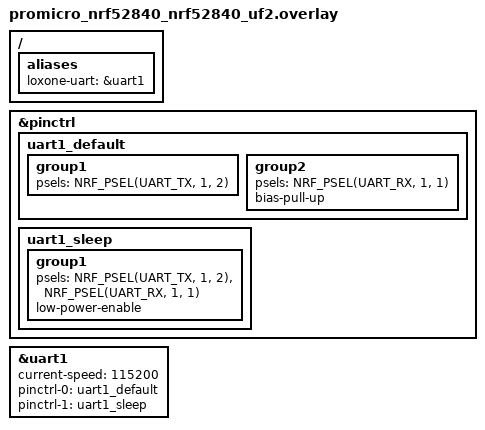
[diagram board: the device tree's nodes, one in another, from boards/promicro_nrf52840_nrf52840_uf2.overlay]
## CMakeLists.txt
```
# SPDX-License-Identifier: Apache-2.0

cmake_minimum_required(VERSION 3.20.0)
find_package(Zephyr REQUIRED HINTS $ENV{ZEPHYR_BASE})
project(Nuki)

target_sources(app PRIVATE
  src/main.c
  src/nuki_crypto.c
  src/nuki_protocol.c
  src/nuki_storage.c
  src/nuki_transport.c
  src/nuki_pairing.c
  src/nuki_command.c
  src/nuki_app.c
  src/nuki_shell.c
  src/nuki_uart_proto.c
)

zephyr_library_include_directories(${ZEPHYR_BASE}/samples/bluetooth)
```

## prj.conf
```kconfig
CONFIG_BT=y
CONFIG_BT_CENTRAL=y
CONFIG_BT_GATT_CLIENT=y
CONFIG_BT_GATT_DM=y
CONFIG_BT_SMP=n
CONFIG_BT_MAX_CONN=1
CONFIG_BT_DEVICE_NAME="Nuki Central"

# Nuki uses its own app-layer crypto (Curve25519 + HSalsa20/Salsa20 +
# Poly1305 + HMAC-SHA256), not BLE link-layer pairing/bonding.
CONFIG_PSA_CRYPTO=y
CONFIG_PSA_CRYPTO_SYS_INIT=y
CONFIG_PSA_WANT_ALG_ECDH=y
CONFIG_PSA_WANT_ECC_MONTGOMERY_255=y
CONFIG_PSA_WANT_KEY_TYPE_ECC_KEY_PAIR_GENERATE=y
CONFIG_PSA_WANT_KEY_TYPE_ECC_KEY_PAIR_IMPORT=y
CONFIG_PSA_WANT_KEY_TYPE_ECC_KEY_PAIR_EXPORT=y
CONFIG_PSA_WANT_ALG_HMAC=y
CONFIG_PSA_WANT_ALG_SHA_256=y
CONFIG_PSA_WANT_KEY_TYPE_HMAC=y
CONFIG_PSA_WANT_KEY_TYPE_RAW_DATA=y

# Persist pairing credentials (authorization id + shared secret) across reboots.
CONFIG_SETTINGS=y
CONFIG_NVS=y
CONFIG_SETTINGS_NVS=y
CONFIG_FLASH=y
CONFIG_FLASH_MAP=y

# Interactive control (no phone app in this project): nuki pair/lock/unlock/unlatch/state.
CONFIG_SHELL=y
CONFIG_SHELL_STACK_SIZE=4096
CONFIG_CBPRINTF_FP_SUPPORT=y

# Without this, every LOG_INF/LOG_ERR/LOG_WRN call in the app is compiled
# out entirely - only explicit shell_print/shell_error output would show.
# Immediate mode (rather than deferred) avoids silently dropping messages
# when scanning generates a burst of log lines faster than they can be
# printed over UART.
CONFIG_LOG=y
CONFIG_LOG_MODE_IMMEDIATE=y

# Larger ATT MTU so a full Nuki frame fits in a single GATT write instead of
# requiring the long-write (prepare/execute) procedure.
CONFIG_BT_L2CAP_TX_MTU=251
CONFIG_BT_BUF_ACL_RX_SIZE=251
CONFIG_BT_BUF_ACL_TX_SIZE=251

CONFIG_MAIN_STACK_SIZE=4096
CONFIG_HEAP_MEM_POOL_SIZE=8192

# Default (1200B) is too small once scan/GATT callbacks (device_found(),
# AD parsing, logging) do more than trivial work - all such callbacks run
# on this thread. Caused an MPU stack-overflow fault during scanning.
CONFIG_BT_RX_STACK_SIZE=4096

# Second UART (uart1, see boards/nrf52840dk_nrf52840.overlay) carrying the
# plain-text machine protocol for the external Loxone module - kept
# separate from the interactive shell/log console on uart0.
CONFIG_UART_INTERRUPT_DRIVEN=y
```

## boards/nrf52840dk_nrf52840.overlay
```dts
/*
 * Enables the DK's second UART (uart1) for the Loxone module machine
 * protocol (see nuki_uart_proto.c).
 *
 * Uses the board's own default "Arduino Serial" pins for uart1 - P1.01 (RX)
 * and P1.02 (TX) - instead of custom pinctrl. An earlier revision of this
 * overlay moved uart1 to P0.20/P0.22 (planned to match the final custom
 * Loxone-module PCB's pinout), but those turned out to be hard-wired on the
 * DK to the onboard QSPI flash chip's IO0/IO2 lines (P0.17/19-23), which
 * caused unreliable/no communication on uart1. P1.01/P1.02 aren't connected
 * to any onboard peripheral, so switched back to them for reliable testing
 * on this DK - the final custom PCB (no onboard QSPI flash) can use whatever
 * pins fit its own layout without this constraint.
 *
 *   P1.02 = TX (board transmits) -> wire to the Loxone module's RX
 *   P1.01 = RX (board receives)  -> wire to the Loxone module's TX
 * plus a common GND between the two boards.
 *
 * On the nRF52840 DK itself, P1.01/P1.02 are broken out on the Arduino
 * shield connector as D0/D1.
 */

/ {
	aliases {
		loxone-uart = &uart1;
	};
};

&uart1 {
	status = "okay";
	current-speed = <115200>;
};

/*
 * The DK's onboard QSPI flash chip (MX25R6435F) is hard-wired to P0.17/19-23.
 * This project doesn't use the external flash (settings/NVS use internal
 * flash), so disable the QSPI peripheral - harmless either way now that
 * uart1 no longer shares any of those pins, but no reason to leave an
 * unused peripheral active.
 */
&qspi {
	status = "disabled";
};
```

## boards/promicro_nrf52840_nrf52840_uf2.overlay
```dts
/*
 * Enables uart1 with custom pinctrl for the Loxone module machine protocol
 * (see nuki_uart_proto.c), on P1.01 (RX) / P1.02 (TX) - the same physical
 * nRF52840 pins used for uart1 on the nRF52840 DK
 * (boards/nrf52840dk_nrf52840.overlay), so both boards are wired identically
 * for the Loxone module regardless of which one is used.
 *
 * uart1 isn't touched by this board's own default devicetree (only uart0,
 * on P0.09/P0.10, is - used here for nothing since the console/shell runs
 * over USB CDC-ACM instead, see promicro_nrf52840_nrf52840_common.dts), and
 * P1.01/P1.02 aren't claimed by i2c0/i2c1/spi2/pwm0 either, so there's no
 * pin conflict enabling uart1 here.
 *
 *   P1.02 = TX (board transmits) -> wire to the Loxone module's RX
 *   P1.01 = RX (board receives)  -> wire to the Loxone module's TX
 * plus a common GND between the two boards.
 */

&pinctrl {
	uart1_default: uart1_default {
		group1 {
			psels = <NRF_PSEL(UART_TX, 1, 2)>;
		};
		group2 {
			psels = <NRF_PSEL(UART_RX, 1, 1)>;
			bias-pull-up;
		};
	};

	uart1_sleep: uart1_sleep {
		group1 {
			psels = <NRF_PSEL(UART_TX, 1, 2)>,
				<NRF_PSEL(UART_RX, 1, 1)>;
			low-power-enable;
		};
	};
};

/ {
	aliases {
		loxone-uart = &uart1;
	};
};

&uart1 {
	status = "okay";
	current-speed = <115200>;
	pinctrl-0 = <&uart1_default>;
	pinctrl-1 = <&uart1_sleep>;
	pinctrl-names = "default", "sleep";
};
```

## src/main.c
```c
/* main.c - Nuki Smart Lock BLE controller.
 *
 * Scans for and connects to a Nuki Smart Lock (1st-4th Generation),
 * discovers its Pairing and Keyturner GATT services, and lets the user
 * pair with it and control it (lock/unlock/unlatch, read state) via the
 * "nuki" shell command (see nuki_shell.c) on uart0, or via the plain-text
 * machine protocol for an external Loxone module on uart1 (see
 * nuki_uart_proto.c). All actual protocol/crypto work lives in
 * nuki_crypto/nuki_protocol/nuki_pairing/nuki_command/nuki_app.
 */

#include <zephyr/kernel.h>
#include <zephyr/sys/printk.h>
#include <zephyr/bluetooth/bluetooth.h>
#include <zephyr/settings/settings.h>

#include "nuki_crypto.h"
#include "nuki_app.h"
#include "nuki_uart_proto.h"

int main(void)
{
	int err;

	err = bt_enable(NULL);
	if (err) {
		printk("Bluetooth init failed (err %d)\n", err);
		return 0;
	}
	printk("Bluetooth initialized\n");

	err = nuki_crypto_init();
	if (err) {
		printk("Crypto init failed (err %d)\n", err);
		return 0;
	}

	err = settings_subsys_init();
	if (err) {
		printk("Settings subsys init failed (err %d)\n", err);
		return 0;
	}
	settings_load();

	nuki_app_init();

	err = nuki_uart_proto_init();
	if (err) {
		printk("Loxone module UART protocol init failed (err %d) - continuing without it\n",
		       err);
	}

	return 0;
}
```

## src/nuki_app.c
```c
#include "nuki_app.h"
#include "nuki_protocol.h"
#include "nuki_transport.h"
#include "nuki_pairing.h"
#include "nuki_command.h"
#include "nuki_storage.h"

#include <string.h>
#include <zephyr/kernel.h>
#include <zephyr/bluetooth/bluetooth.h>
#include <zephyr/bluetooth/hci.h>
#include <zephyr/bluetooth/conn.h>
#include <zephyr/bluetooth/uuid.h>
#include <zephyr/bluetooth/gatt.h>
#include <bluetooth/gatt_dm.h>
#include <zephyr/logging/log.h>

LOG_MODULE_REGISTER(nuki_app, LOG_LEVEL_INF);

/*
 * Most Nuki Smart Locks (1st-3rd Generation) only accept a single BLE
 * connection at a time. To avoid permanently hogging that one slot (which
 * would block the official Nuki app from ever connecting directly), this
 * module connects only for the duration of one operation - pair/get-state/
 * lock-action/calibrate - and disconnects again immediately afterwards,
 * instead of staying connected in the background.
 */

#define SCAN_TIMEOUT_SEC 15
#define SCAN_TIMEOUT K_SECONDS(SCAN_TIMEOUT_SEC)
#define CONNECT_TIMEOUT K_SECONDS(20)
#define DISCONNECT_TIMEOUT K_SECONDS(5)

/* Short connection interval (15 ms, in 1.25 ms units), no peripheral
 * latency, 4 s supervision timeout - every operation here is a handful of
 * sequential GATT round trips, so a short interval matters more than power
 * use for a device that's only connected for a couple of seconds at a time.
 * Not using the BLE-minimum 7.5 ms: that proved less robust (occasional
 * "failed to establish, RF noise?" connection failures) in a busy 2.4 GHz
 * environment - 15 ms is still 2-3x faster than the usual ~30-50 ms default
 * while leaving more margin for the radio to sync reliably.
 */
#define NUKI_CONN_PARAM BT_LE_CONN_PARAM(0x000C, 0x000C, 0, 400)

static struct bt_conn *g_conn;
static struct nuki_transport g_gdio;
static struct nuki_transport g_usdio;
static bool g_gdio_ready;
static bool g_usdio_ready;
static bool g_need_gdio; /* whether the in-progress connect() needs the
			   * Pairing Service (only nuki_app_pair() does).
			   */

/* Given once the connect+discovery sequence reaches a terminal state
 * (fully ready, or any failure) - see connect_to_lock().
 */
static struct k_sem g_ready_sem;
static int g_connect_err;
static bool g_connecting; /* true from connect_to_lock() until the first
			    * finish_connect_attempt() call for this attempt.
			    */

/* Given once disconnected() has finished cleaning up - see
 * disconnect_from_lock().
 */
static struct k_sem g_disconnected_sem;

static struct k_work_delayable g_scan_timeout_work;

/* Serializes all BLE operations (pair/get-state/lock-action/calibrate):
 * the shell (uart0), the Loxone machine protocol (uart1) and the periodic
 * status poller below can all trigger one of these independently, but the
 * connect/discover/operate/disconnect state machine above is not written
 * to handle two callers at once.
 */
static struct k_mutex g_op_lock;

/* --- periodic status cache --------------------------------------------- */

/* How often to poll the lock's state in the background so a UART query
 * (see nuki_uart_proto.c) can answer instantly from cache instead of
 * paying for a fresh BLE connect+read (a couple of seconds) every time.
 * 15 min, in line with the official Nuki Bridge's default poll interval
 * (30 min) - frequent enough for Loxone, without materially shortening the
 * lock's own battery life via extra connection cycles.
 */
#define STATE_POLL_INTERVAL_SEC (15 * 60)

/* If a poll fails (e.g. a transient BLE hiccup like a stalled discovery),
 * retry sooner instead of leaving the cache stale for the full interval -
 * but only a bounded number of times, so a persistently unreachable lock
 * doesn't turn into a tight retry loop.
 */
#define STATE_POLL_RETRY_SEC 3
#define STATE_POLL_MAX_RETRIES 3
/* Must match the uart1 protocol thread's stack size (see
 * THREAD_STACK_SIZE in nuki_uart_proto.c) - this thread runs the exact same
 * deep call chain (connect_to_lock() -> GATT discovery -> encrypt/decrypt)
 * via nuki_app_get_state(). 2048 was enough to never crash in quick manual
 * testing, but overflowed intermittently here over long unattended runtime
 * (same class of bug that was first caught on the uart1 thread during a
 * LOCK test) - a stack overflow halts the whole system (no watchdog/auto-
 * reboot configured), and since it happens while g_op_lock is held, every
 * other caller (shell, uart1) then blocks forever waiting for that mutex
 * too, looking exactly like "the firmware hangs and uart1 stops responding".
 */
#define STATE_POLL_THREAD_STACK_SIZE 4096
#define STATE_POLL_THREAD_PRIORITY 7

/* Runs on its own dedicated thread rather than the system workqueue: the
 * poll blocks for several seconds inside connect_to_lock(), and the system
 * workqueue is shared with the Bluetooth host's own background work (e.g.
 * connection housekeeping) - tying it up caused GATT discovery to
 * occasionally stall for the full connect timeout during a background poll,
 * even though the exact same operation triggered manually (on the shell's
 * own thread) never showed the problem.
 */
static K_THREAD_STACK_DEFINE(state_poll_thread_stack, STATE_POLL_THREAD_STACK_SIZE);
static struct k_thread state_poll_thread_data;
static uint8_t g_state_poll_retries;
static struct k_mutex g_cache_lock;
static struct nuki_keyturner_state g_cached_state;
static bool g_cache_valid;
static int64_t g_cache_uptime_ms;

/* --- advertising data matching -------------------------------------------- */

struct uuid_match_ctx {
	const struct bt_uuid *target;
	bool found;
};

static bool uuid128_matches(const uint8_t *bytes, const struct bt_uuid *target)
{
	struct bt_uuid_128 candidate;

	candidate.uuid.type = BT_UUID_TYPE_128;
	memcpy(candidate.val, bytes, 16);
	return bt_uuid_cmp(&candidate.uuid, target) == 0;
}

static bool ad_uuid_cb(struct bt_data *data, void *user_data)
{
	struct uuid_match_ctx *ctx = user_data;

	switch (data->type) {
	case BT_DATA_UUID128_ALL:
	case BT_DATA_UUID128_SOME:
		/* A concatenated list of 16-byte UUIDs. */
		for (size_t i = 0; i + 16 <= data->data_len; i += 16) {
			if (uuid128_matches(&data->data[i], ctx->target)) {
				ctx->found = true;
				return false;
			}
		}
		break;
	case BT_DATA_SVC_DATA128:
		/* Service Data (128-bit UUID): the first 16 bytes are the
		 * UUID, followed by service-specific payload. Nuki locks
		 * advertise this way (e.g. their own lock-state "beacon"
		 * data) rather than via a plain service UUID list.
		 */
		if (data->data_len >= 16 && uuid128_matches(data->data, ctx->target)) {
			ctx->found = true;
			return false;
		}
		break;
	default:
		break;
	}
	return true;
}

static bool ad_has_uuid(struct net_buf_simple *ad, const struct bt_uuid *target)
{
	struct uuid_match_ctx ctx = {.target = target, .found = false};
	struct net_buf_simple copy;

	net_buf_simple_clone(ad, &copy);
	bt_data_parse(&copy, ad_uuid_cb, &ctx);
	return ctx.found;
}

static bool ad_name_cb(struct bt_data *data, void *user_data)
{
	char *name = user_data;

	if (data->type == BT_DATA_NAME_COMPLETE || data->type == BT_DATA_NAME_SHORTENED) {
		size_t len = MIN(data->data_len, 30);

		memcpy(name, data->data, len);
		name[len] = '\0';
		return false;
	}
	return true;
}

static void ad_get_name(struct net_buf_simple *ad, char *out, size_t out_size)
{
	struct net_buf_simple copy;

	out[0] = '\0';
	net_buf_simple_clone(ad, &copy);
	bt_data_parse(&copy, ad_name_cb, out);
	ARG_UNUSED(out_size); /* ad_name_cb already caps at 30 chars, see log_advertisement */
}

/* Nuki locks advertise as "Nuki_<8 hex chars>" (confirmed on real hardware -
 * see the "adv seen" diagnostic log). This is checked in addition to the
 * service UUID / service-data matching below, since which AD field actually
 * carries the service identifier can vary/be missed depending on timing.
 */
#define NUKI_NAME_PREFIX "Nuki_"

static bool ad_has_nuki_name(struct net_buf_simple *ad)
{
	char name[31];

	ad_get_name(ad, name, sizeof(name));
	return strncmp(name, NUKI_NAME_PREFIX, strlen(NUKI_NAME_PREFIX)) == 0;
}

/* Diagnostic aid used while dialing in the scan filter: logs every
 * advertisement seen during a scan window. Left in at LOG_DBG (compiled out
 * by the module's LOG_LEVEL_INF registration below, so no runtime cost) in
 * case scan-matching ever needs to be debugged again - bump the module's
 * registered level to LOG_LEVEL_DBG to re-enable.
 */
static void log_advertisement(const bt_addr_le_t *addr, int8_t rssi, uint8_t type,
			       struct net_buf_simple *ad)
{
	char addr_str[BT_ADDR_LE_STR_LEN];
	char name[31];

	bt_addr_le_to_str(addr, addr_str, sizeof(addr_str));
	ad_get_name(ad, name, sizeof(name));

	LOG_DBG("adv seen: %s rssi=%d type=%u name=\"%s\" ad_len=%u", addr_str, rssi, type, name,
		ad->len);
}

static void finish_connect_attempt(int err)
{
	/* Guard against a late/duplicate call (e.g. disconnected() firing
	 * shortly after an earlier discovery failure already disconnected
	 * and reported its own error) clobbering the result that was
	 * already recorded and may already have been consumed.
	 */
	if (!g_connecting) {
		return;
	}
	g_connecting = false;

	g_connect_err = err;
	k_work_cancel_delayable(&g_scan_timeout_work);
	k_sem_give(&g_ready_sem);
}

static void device_found(const bt_addr_le_t *addr, int8_t rssi, uint8_t type,
			  struct net_buf_simple *ad)
{
	int err;

	if (g_conn) {
		return;
	}

	log_advertisement(addr, rssi, type, ad);

	/*
	 * Deliberately not filtering by adv `type` here: many peripherals
	 * (including Nuki locks) put their 128-bit service UUID list in the
	 * scan response rather than the primary advertising PDU to fit
	 * within the legacy 31-byte AD budget. With active scanning we get a
	 * separate callback invocation per PDU (primary adv AND scan
	 * response), so the UUID match below needs to run against both.
	 * A non-connectable match would simply fail in bt_conn_le_create()
	 * below, which is harmless.
	 */
	const struct nuki_pairing_data *paired = nuki_storage_get_pairing();
	bool match;

	if (paired) {
		match = bt_addr_le_cmp(addr, &paired->addr) == 0;
	} else {
		match = ad_has_uuid(ad, &nuki_keyturner_service_uuid.uuid) || ad_has_nuki_name(ad);
	}

	if (!match) {
		return;
	}

	LOG_INF("Nuki lock found: %s", bt_addr_le_str(addr));

	if (bt_le_scan_stop()) {
		return;
	}
	k_work_cancel_delayable(&g_scan_timeout_work);

	err = bt_conn_le_create(addr, BT_CONN_LE_CREATE_CONN, NUKI_CONN_PARAM, &g_conn);
	if (err) {
		LOG_ERR("create conn failed (%d)", err);
		finish_connect_attempt(err);
	}
}

static void scan_timeout_handler(struct k_work *work)
{
	ARG_UNUSED(work);
	bt_le_scan_stop();
	LOG_WRN("no Nuki lock found within %d s", SCAN_TIMEOUT_SEC);
	finish_connect_attempt(-ETIMEDOUT);
}

/* --- GATT discovery -------------------------------------------------------- */

static void usdio_discovered(struct bt_gatt_dm *dm, void *ctx);

static void usdio_not_found(struct bt_conn *conn, void *ctx)
{
	ARG_UNUSED(ctx);
	LOG_ERR("Keyturner service not found - disconnecting");
	bt_conn_disconnect(conn, BT_HCI_ERR_REMOTE_USER_TERM_CONN);
	finish_connect_attempt(-ENOTSUP);
}

static void usdio_discovery_error(struct bt_conn *conn, int err, void *ctx)
{
	ARG_UNUSED(ctx);
	LOG_ERR("Keyturner service discovery failed (%d) - disconnecting", err);
	bt_conn_disconnect(conn, BT_HCI_ERR_REMOTE_USER_TERM_CONN);
	finish_connect_attempt(-EIO);
}

static const struct bt_gatt_dm_cb usdio_dm_cb = {
	.completed = usdio_discovered,
	.service_not_found = usdio_not_found,
	.error_found = usdio_discovery_error,
};

static void discover_keyturner_service(struct bt_conn *conn)
{
	int rc = bt_gatt_dm_start(conn, &nuki_keyturner_service_uuid.uuid, &usdio_dm_cb, NULL);

	if (rc) {
		LOG_ERR("gatt_dm_start (keyturner service) failed (%d)", rc);
		finish_connect_attempt(rc);
	}
}

static void gdio_not_found(struct bt_conn *conn, void *ctx)
{
	ARG_UNUSED(ctx);
	/* A missing Pairing Service isn't fatal here - a lock that is
	 * already paired with someone else may not offer it, but the
	 * Keyturner Service (discovered next) is what normal operation
	 * actually needs.
	 */
	discover_keyturner_service(conn);
}

static void gdio_discovery_error(struct bt_conn *conn, int err, void *ctx)
{
	ARG_UNUSED(err);
	ARG_UNUSED(ctx);
	discover_keyturner_service(conn);
}

static void gdio_discovered(struct bt_gatt_dm *dm, void *ctx)
{
	const struct bt_gatt_dm_attr *chrc, *ccc;
	struct bt_gatt_chrc *chrc_val;
	struct bt_conn *conn = bt_gatt_dm_conn_get(dm);

	chrc = bt_gatt_dm_char_by_uuid(dm, &nuki_pairing_gdio_uuid.uuid);
	if (!chrc) {
		LOG_ERR("GDIO characteristic not found");
	} else {
		chrc_val = bt_gatt_dm_attr_chrc_val(chrc);
		ccc = bt_gatt_dm_desc_by_uuid(dm, chrc, BT_UUID_GATT_CCC);

		if (nuki_transport_init(&g_gdio, conn, chrc_val->value_handle,
					 ccc ? ccc->handle : 0) == 0) {
			g_gdio_ready = true;
			LOG_INF("Pairing service discovered");
		}
	}

	bt_gatt_dm_data_release(dm);
	discover_keyturner_service(conn);
}

static const struct bt_gatt_dm_cb gdio_dm_cb = {
	.completed = gdio_discovered,
	.service_not_found = gdio_not_found,
	.error_found = gdio_discovery_error,
};

static void usdio_discovered(struct bt_gatt_dm *dm, void *ctx)
{
	const struct bt_gatt_dm_attr *chrc, *ccc;
	struct bt_gatt_chrc *chrc_val;

	chrc = bt_gatt_dm_char_by_uuid(dm, &nuki_keyturner_usdio_uuid.uuid);
	if (!chrc) {
		LOG_ERR("USDIO characteristic not found");
		bt_gatt_dm_data_release(dm);
		finish_connect_attempt(-ENOTSUP);
		return;
	}
	chrc_val = bt_gatt_dm_attr_chrc_val(chrc);
	ccc = bt_gatt_dm_desc_by_uuid(dm, chrc, BT_UUID_GATT_CCC);

	int err = nuki_transport_init(&g_usdio, bt_gatt_dm_conn_get(dm), chrc_val->value_handle,
				       ccc ? ccc->handle : 0);

	bt_gatt_dm_data_release(dm);

	if (err) {
		finish_connect_attempt(err);
		return;
	}

	g_usdio_ready = true;
	LOG_INF("Keyturner service discovered - ready");
	finish_connect_attempt(0);
}

static void start_discovery(struct bt_conn *conn)
{
	int err;

	if (!g_need_gdio) {
		/* state/lock/unlock/calibrate only ever use the Keyturner
		 * Service - skip the Pairing Service discovery round trip
		 * entirely (saves roughly a second per command).
		 */
		discover_keyturner_service(conn);
		return;
	}

	err = bt_gatt_dm_start(conn, &nuki_pairing_service_uuid.uuid, &gdio_dm_cb, NULL);
	if (err) {
		LOG_ERR("gatt_dm_start (pairing service) failed (%d)", err);
		finish_connect_attempt(err);
	}
}

/* --- connection callbacks --------------------------------------------------- */

static void connected(struct bt_conn *conn, uint8_t err)
{
	if (err) {
		LOG_ERR("failed to connect: %s", bt_hci_err_to_str(err));
		bt_conn_unref(g_conn);
		g_conn = NULL;
		finish_connect_attempt(-EIO);
		return;
	}

	if (conn != g_conn) {
		return;
	}

	LOG_INF("connected: %s", bt_conn_dst_str(conn));
	start_discovery(conn);
}

static void disconnected(struct bt_conn *conn, uint8_t reason)
{
	if (conn != g_conn) {
		return;
	}

	LOG_INF("disconnected: 0x%02x %s", reason, bt_hci_err_to_str(reason));

	if (g_gdio_ready) {
		nuki_transport_release(&g_gdio);
		g_gdio_ready = false;
	}
	if (g_usdio_ready) {
		nuki_transport_release(&g_usdio);
		g_usdio_ready = false;
	}

	bt_conn_unref(g_conn);
	g_conn = NULL;

	/* If we disconnected before connect_to_lock()'s wait was satisfied
	 * (e.g. the lock dropped the link mid-discovery), unblock it with an
	 * error instead of leaving it to wait out the full connect timeout.
	 */
	finish_connect_attempt(-ENOTCONN);
	k_sem_give(&g_disconnected_sem);
}

BT_CONN_CB_DEFINE(conn_callbacks) = {
	.connected = connected,
	.disconnected = disconnected,
};

/* --- connect-on-demand helpers ---------------------------------------------- */

static int connect_to_lock(bool need_gdio)
{
	int err;

	k_sem_reset(&g_ready_sem);
	g_connect_err = 0;
	g_need_gdio = need_gdio;
	g_connecting = true;

	/* _CONTINUOUS sets scan window == interval (100% duty cycle) instead
	 * of the ~50% default, so we don't miss/delay catching the lock's
	 * next advertisement while the radio is "off" between windows.
	 */
	err = bt_le_scan_start(BT_LE_SCAN_ACTIVE_CONTINUOUS, device_found);
	if (err) {
		LOG_ERR("scanning failed to start (%d)", err);
		return err;
	}
	LOG_INF("scanning for Nuki lock...");
	k_work_schedule(&g_scan_timeout_work, SCAN_TIMEOUT);

	err = k_sem_take(&g_ready_sem, CONNECT_TIMEOUT);
	if (err) {
		LOG_ERR("timed out connecting to the lock");
		g_connecting = false;
		bt_le_scan_stop();
		if (g_conn) {
			bt_conn_disconnect(g_conn, BT_HCI_ERR_REMOTE_USER_TERM_CONN);
		}
		return -ETIMEDOUT;
	}

	return g_connect_err;
}

static void disconnect_from_lock(void)
{
	if (!g_conn) {
		return;
	}
	k_sem_reset(&g_disconnected_sem);
	bt_conn_disconnect(g_conn, BT_HCI_ERR_REMOTE_USER_TERM_CONN);
	k_sem_take(&g_disconnected_sem, DISCONNECT_TIMEOUT);
}

/* --- periodic status polling ------------------------------------------- */

static void state_poll_thread_fn(void *p1, void *p2, void *p3)
{
	ARG_UNUSED(p1);
	ARG_UNUSED(p2);
	ARG_UNUSED(p3);
	struct nuki_keyturner_state state;
	int err;
	k_timeout_t next;

	while (1) {
		next = K_SECONDS(STATE_POLL_INTERVAL_SEC);

		/* Only poll once actually paired - otherwise every poll would
		 * just fail with -ENOENT and spam the log. Not being paired
		 * isn't a transient failure, so it doesn't consume a retry.
		 */
		if (nuki_app_is_paired()) {
			LOG_INF("background state poll starting");
			err = nuki_app_get_state(&state);
			if (!err) {
				k_mutex_lock(&g_cache_lock, K_FOREVER);
				g_cached_state = state;
				g_cache_valid = true;
				g_cache_uptime_ms = k_uptime_get();
				k_mutex_unlock(&g_cache_lock);
				LOG_INF("background state poll succeeded");
				g_state_poll_retries = 0;
			} else if (g_state_poll_retries < STATE_POLL_MAX_RETRIES) {
				g_state_poll_retries++;
				LOG_WRN("background state poll failed (%d) - retry %u/%u in %ds",
					err, g_state_poll_retries, STATE_POLL_MAX_RETRIES,
					STATE_POLL_RETRY_SEC);
				next = K_SECONDS(STATE_POLL_RETRY_SEC);
			} else {
				LOG_WRN("background state poll failed (%d) - giving up after %u "
					"retries, next attempt in %d min",
					err, g_state_poll_retries, STATE_POLL_INTERVAL_SEC / 60);
				g_state_poll_retries = 0;
			}
		}

		k_sleep(next);
	}
}

/* --- public API -------------------------------------------------------------- */

int nuki_app_init(void)
{
	k_sem_init(&g_ready_sem, 0, 1);
	k_sem_init(&g_disconnected_sem, 0, 1);
	k_mutex_init(&g_op_lock);
	k_mutex_init(&g_cache_lock);
	k_work_init_delayable(&g_scan_timeout_work, scan_timeout_handler);

	k_thread_create(&state_poll_thread_data, state_poll_thread_stack,
			STATE_POLL_THREAD_STACK_SIZE, state_poll_thread_fn, NULL, NULL, NULL,
			K_PRIO_COOP(STATE_POLL_THREAD_PRIORITY), 0, K_NO_WAIT);
	k_thread_name_set(&state_poll_thread_data, "nuki_state_poll");
	return 0;
}

bool nuki_app_is_connected(void)
{
	return g_conn != NULL;
}

bool nuki_app_is_ready(void)
{
	return g_conn != NULL && g_usdio_ready;
}

bool nuki_app_is_paired(void)
{
	return nuki_storage_get_pairing() != NULL;
}

/* Returns the most recent state captured by the background poller (see
 * state_poll_handler above) without touching BLE at all. *age_sec is set to
 * how many seconds old that snapshot is. Returns -ENODATA if no successful
 * poll has completed yet (e.g. right after boot).
 */
int nuki_app_get_cached_state(struct nuki_keyturner_state *out, int32_t *age_sec)
{
	int err = 0;

	k_mutex_lock(&g_cache_lock, K_FOREVER);
	if (g_cache_valid) {
		*out = g_cached_state;
		*age_sec = (int32_t)((k_uptime_get() - g_cache_uptime_ms) / 1000);
	} else {
		err = -ENODATA;
	}
	k_mutex_unlock(&g_cache_lock);

	return err;
}

static int pair_locked(void)
{
	struct nuki_pairing_data data;
	int err;

	err = connect_to_lock(true);
	if (err) {
		return err;
	}

	if (!g_gdio_ready) {
		LOG_ERR("lock did not offer the Pairing Service on this connection");
		disconnect_from_lock();
		return -ENOTSUP;
	}

	err = nuki_pairing_run(&g_gdio, &data);
	if (!err) {
		bt_addr_le_copy(&data.addr, bt_conn_get_dst(g_conn));
		err = nuki_storage_save_pairing(&data);
	}

	disconnect_from_lock();
	return err;
}

static int get_state_locked(struct nuki_keyturner_state *out)
{
	const struct nuki_pairing_data *p = nuki_storage_get_pairing();
	int err;

	if (!p) {
		return -ENOENT;
	}

	err = connect_to_lock(false);
	if (err) {
		return err;
	}

	err = nuki_command_get_state(&g_usdio, p->auth_id, p->shared_key, out);
	disconnect_from_lock();
	return err;
}

static int lock_action_locked(uint8_t action)
{
	const struct nuki_pairing_data *p = nuki_storage_get_pairing();
	struct nuki_keyturner_state state;
	bool got_state;
	int err;

	if (!p) {
		return -ENOENT;
	}

	err = connect_to_lock(false);
	if (err) {
		return err;
	}

	err = nuki_command_lock_action(&g_usdio, p->auth_id, p->app_id, p->shared_key, action,
					&state, &got_state);
	disconnect_from_lock();

	/* The lock conveniently pushes its post-action state as part of the
	 * action sequence (see nuki_command_lock_action()) - update the cache
	 * from it right away instead of waiting for the next background poll,
	 * at no extra BLE cost since we're already connected for the action
	 * anyway.
	 */
	if (!err && got_state) {
		k_mutex_lock(&g_cache_lock, K_FOREVER);
		g_cached_state = state;
		g_cache_valid = true;
		g_cache_uptime_ms = k_uptime_get();
		k_mutex_unlock(&g_cache_lock);
		LOG_INF("cache updated from lock-action response");
	}

	return err;
}

static int calibrate_locked(uint16_t security_pin)
{
	const struct nuki_pairing_data *p = nuki_storage_get_pairing();
	int err;

	if (!p) {
		return -ENOENT;
	}

	err = connect_to_lock(false);
	if (err) {
		return err;
	}

	err = nuki_command_calibrate(&g_usdio, p->auth_id, p->shared_key, security_pin);
	disconnect_from_lock();
	return err;
}

int nuki_app_pair(void)
{
	int err;

	k_mutex_lock(&g_op_lock, K_FOREVER);
	err = pair_locked();
	k_mutex_unlock(&g_op_lock);
	return err;
}

int nuki_app_get_state(struct nuki_keyturner_state *out)
{
	int err;

	k_mutex_lock(&g_op_lock, K_FOREVER);
	err = get_state_locked(out);
	k_mutex_unlock(&g_op_lock);
	return err;
}

int nuki_app_lock_action(uint8_t action)
{
	int err;

	k_mutex_lock(&g_op_lock, K_FOREVER);
	err = lock_action_locked(action);
	k_mutex_unlock(&g_op_lock);
	return err;
}

int nuki_app_calibrate(uint16_t security_pin)
{
	int err;

	k_mutex_lock(&g_op_lock, K_FOREVER);
	err = calibrate_locked(security_pin);
	k_mutex_unlock(&g_op_lock);
	return err;
}
```

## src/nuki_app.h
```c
/* nuki_app.h - top-level orchestration: scan for the Nuki lock, connect,
 * discover the Pairing and Keyturner services, and expose blocking
 * pair/get-state/lock-action operations for nuki_shell.c to call into.
 */
#ifndef NUKI_APP_H_
#define NUKI_APP_H_

#include <stdbool.h>
#include "nuki_protocol.h"

/* Call once at boot, after bt_enable() and settings_load(). Starts
 * scanning for the lock (by stored address if already paired, otherwise by
 * the Keyturner Service UUID) and connects/discovers automatically.
 */
int nuki_app_init(void);

bool nuki_app_is_connected(void);
bool nuki_app_is_ready(void); /* connected AND both services discovered */
bool nuki_app_is_paired(void);

/* Runs the pairing handshake (lock must be in pairing mode - button held
 * 5s). Blocks until it completes, fails, or times out. Persists the result
 * on success.
 */
int nuki_app_pair(void);

int nuki_app_get_state(struct nuki_keyturner_state *out);
int nuki_app_lock_action(uint8_t action);

/* Returns the most recent state captured by the background poller (roughly
 * every 15 min, see nuki_app.c) without touching BLE - use this for a fast
 * status query (e.g. from the Loxone UART protocol) instead of
 * nuki_app_get_state(), which always does a live BLE round trip. *age_sec
 * is set to how many seconds old the returned snapshot is. Returns
 * -ENODATA if no poll has completed successfully yet.
 */
int nuki_app_get_cached_state(struct nuki_keyturner_state *out, int32_t *age_sec);

/* Triggers lock calibration (full-range motor run to relearn the
 * mechanical end-stops - the same action the Nuki app performs during
 * initial setup). Requires the lock's Security-PIN.
 */
int nuki_app_calibrate(uint16_t security_pin);

#endif /* NUKI_APP_H_ */
```

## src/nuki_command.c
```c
#include "nuki_command.h"
#include "nuki_crypto.h"

#include <string.h>
#include <errno.h>
#include <zephyr/logging/log.h>
#include <zephyr/random/random.h>
#include <zephyr/sys/byteorder.h>

LOG_MODULE_REGISTER(nuki_command, LOG_LEVEL_INF);

#define ADATA_HDR_LEN 30 /* nonce(24) + authId(4) + msgLen(2) */
#define RECV_TIMEOUT K_SECONDS(10)
#define MAX_PLAINTEXT 200

static int send_encrypted(struct nuki_transport *usdio, uint32_t auth_id,
			   const uint8_t shared_key[NUKI_KEY_LEN], uint16_t cmd,
			   const uint8_t *payload, size_t payload_len)
{
	uint8_t plain[NUKI_FRAME_MAX_LEN];
	uint8_t nonce[NUKI_NONCE_LEN];
	uint8_t wire[ADATA_HDR_LEN + NUKI_TAG_LEN + NUKI_FRAME_MAX_LEN];
	size_t plain_len;
	int err;

	plain_len = nuki_frame_build_auth(plain, sizeof(plain), auth_id, cmd, payload,
					   payload_len);
	if (!plain_len) {
		return -EINVAL;
	}

	sys_rand_get(nonce, sizeof(nonce));

	err = nuki_crypto_e1(wire + ADATA_HDR_LEN, plain, plain_len, nonce, shared_key);
	if (err) {
		return err;
	}

	memcpy(wire, nonce, NUKI_NONCE_LEN);
	sys_put_le32(auth_id, wire + 24);
	sys_put_le16(NUKI_TAG_LEN + plain_len, wire + 28);

	return nuki_transport_write(usdio, wire, ADATA_HDR_LEN + NUKI_TAG_LEN + plain_len);
}

/* Waits for one complete encrypted USDIO message, decrypts and parses it. */
static int recv_encrypted(struct nuki_transport *usdio, const uint8_t shared_key[NUKI_KEY_LEN],
			   uint16_t *cmd, uint8_t *payload_out, size_t *payload_len,
			   size_t payload_max)
{
	uint8_t header[ADATA_HDR_LEN];
	uint8_t nonce[NUKI_NONCE_LEN];
	uint8_t wire[ADATA_HDR_LEN + NUKI_TAG_LEN + MAX_PLAINTEXT];
	uint8_t plain[NUKI_TAG_LEN + MAX_PLAINTEXT];
	size_t ct_len;
	size_t total_len;
	uint32_t frame_auth_id;
	const uint8_t *payload;
	size_t got_len;
	int err;

	err = nuki_transport_wait_min(usdio, ADATA_HDR_LEN, RECV_TIMEOUT);
	if (err) {
		return err;
	}
	nuki_transport_peek(usdio, header, ADATA_HDR_LEN);

	memcpy(nonce, header, NUKI_NONCE_LEN);
	ct_len = sys_get_le16(&header[28]);
	if (ct_len < NUKI_TAG_LEN || ct_len > sizeof(wire) - ADATA_HDR_LEN) {
		LOG_ERR("implausible encrypted message length %zu", ct_len);
		nuki_transport_reset(usdio);
		return -EBADMSG;
	}
	total_len = ADATA_HDR_LEN + ct_len;

	err = nuki_transport_wait_min(usdio, total_len, RECV_TIMEOUT);
	if (err) {
		return err;
	}
	nuki_transport_peek(usdio, wire, total_len);
	nuki_transport_reset(usdio);

	size_t plain_len = ct_len - NUKI_TAG_LEN;

	err = nuki_crypto_d1(plain, wire + ADATA_HDR_LEN, plain_len, nonce, shared_key);
	if (err) {
		LOG_ERR("decrypt/authenticate failed (%d)", err);
		return err;
	}

	err = nuki_frame_parse_auth(plain, plain_len, &frame_auth_id, cmd, &payload, &got_len);
	if (err) {
		LOG_ERR("plaintext frame parse/CRC failed (%d)", err);
		return err;
	}

	if (got_len > payload_max) {
		return -ENOMEM;
	}
	memcpy(payload_out, payload, got_len);
	*payload_len = got_len;

	return 0;
}

int nuki_command_get_state(struct nuki_transport *usdio, uint32_t auth_id,
			    const uint8_t shared_key[NUKI_KEY_LEN],
			    struct nuki_keyturner_state *state)
{
	uint8_t req_payload[2];
	uint8_t payload[MAX_PLAINTEXT];
	size_t payload_len;
	uint16_t cmd;
	int err;

	sys_put_le16(NUKI_CMD_KEYTURNER_STATES, req_payload);
	err = send_encrypted(usdio, auth_id, shared_key, NUKI_CMD_REQUEST_DATA, req_payload,
			     sizeof(req_payload));
	if (err) {
		return err;
	}

	err = recv_encrypted(usdio, shared_key, &cmd, payload, &payload_len, sizeof(payload));
	if (err) {
		return err;
	}
	if (cmd != NUKI_CMD_KEYTURNER_STATES) {
		LOG_ERR("expected KeyturnerStates, got 0x%04x", cmd);
		return -EBADMSG;
	}

	return nuki_keyturner_state_parse(state, payload, payload_len);
}

/* Requests a fresh Challenge and returns its 32-byte nonce. */
static int request_challenge(struct nuki_transport *usdio, uint32_t auth_id,
			      const uint8_t shared_key[NUKI_KEY_LEN], uint8_t nonce_k[32])
{
	uint8_t req_payload[2];
	uint8_t challenge_payload[MAX_PLAINTEXT];
	size_t challenge_len;
	uint16_t cmd;
	int err;

	sys_put_le16(NUKI_CMD_CHALLENGE, req_payload);
	err = send_encrypted(usdio, auth_id, shared_key, NUKI_CMD_REQUEST_DATA, req_payload,
			     sizeof(req_payload));
	if (err) {
		return err;
	}
	err = recv_encrypted(usdio, shared_key, &cmd, challenge_payload, &challenge_len,
			     sizeof(challenge_payload));
	if (err) {
		return err;
	}
	if (cmd != NUKI_CMD_CHALLENGE || challenge_len != 32) {
		LOG_ERR("expected Challenge(32), got 0x%04x/%zu", cmd, challenge_len);
		return -EBADMSG;
	}
	memcpy(nonce_k, challenge_payload, 32);
	return 0;
}

/* Drains responses (Status ACCEPTED, KeyturnerStates updates...) until a
 * terminal Status COMPLETE or an ErrorReport arrives. If state_out/got_state
 * are non-NULL, best-effort captures the first KeyturnerStates update seen
 * along the way (see nuki_command_lock_action()).
 */
static int drain_until_complete(struct nuki_transport *usdio,
				 const uint8_t shared_key[NUKI_KEY_LEN],
				 struct nuki_keyturner_state *state_out, bool *got_state)
{
	if (got_state) {
		*got_state = false;
	}

	for (int i = 0; i < 10; i++) {
		uint8_t payload[MAX_PLAINTEXT];
		size_t payload_len;
		uint16_t cmd;
		int err = recv_encrypted(usdio, shared_key, &cmd, payload, &payload_len,
					  sizeof(payload));

		if (err) {
			return err;
		}

		if (cmd == NUKI_CMD_ERROR_REPORT) {
			LOG_ERR("lock returned ErrorReport (code %d)", (int8_t)payload[0]);
			return -EIO;
		}

		if (cmd == NUKI_CMD_STATUS) {
			if (payload_len != 1) {
				return -EBADMSG;
			}
			if (payload[0] == NUKI_STATUS_COMPLETE) {
				return 0;
			}
			/* ACCEPTED: keep waiting for COMPLETE. */
			continue;
		}

		if (cmd == NUKI_CMD_KEYTURNER_STATES && state_out && got_state) {
			/* A parse failure here isn't fatal to the overall
			 * operation - it just means the caller won't get this
			 * bonus data and will fall back to its existing cache.
			 */
			if (nuki_keyturner_state_parse(state_out, payload, payload_len) == 0) {
				*got_state = true;
			}
			continue;
		}

		/* Other intermediate updates: ignore and keep waiting for the
		 * terminal Status.
		 */
	}

	LOG_ERR("gave up waiting for Status COMPLETE");
	return -ETIMEDOUT;
}

int nuki_command_lock_action(struct nuki_transport *usdio, uint32_t auth_id, uint32_t app_id,
			      const uint8_t shared_key[NUKI_KEY_LEN], uint8_t action,
			      struct nuki_keyturner_state *state_out, bool *got_state)
{
	uint8_t nonce_k[32];
	uint8_t action_payload[1 + 4 + 1 + 32];
	int err;

	err = request_challenge(usdio, auth_id, shared_key, nonce_k);
	if (err) {
		return err;
	}

	/* LockAction: action | appId | flags(0) | nonceK  (no NameSuffix) */
	action_payload[0] = action;
	sys_put_le32(app_id, &action_payload[1]);
	action_payload[5] = 0; /* flags: no auto-unlock, no force */
	memcpy(&action_payload[6], nonce_k, 32);

	err = send_encrypted(usdio, auth_id, shared_key, NUKI_CMD_LOCK_ACTION, action_payload,
			     sizeof(action_payload));
	if (err) {
		return err;
	}

	return drain_until_complete(usdio, shared_key, state_out, got_state);
}

int nuki_command_calibrate(struct nuki_transport *usdio, uint32_t auth_id,
			    const uint8_t shared_key[NUKI_KEY_LEN], uint16_t security_pin)
{
	uint8_t nonce_k[32];
	uint8_t payload[32 + 2];
	int err;

	err = request_challenge(usdio, auth_id, shared_key, nonce_k);
	if (err) {
		return err;
	}

	/* Request Calibration: nonceK | Security-PIN (uint16, Gen 1-4). */
	memcpy(payload, nonce_k, 32);
	sys_put_le16(security_pin, &payload[32]);

	err = send_encrypted(usdio, auth_id, shared_key, NUKI_CMD_REQUEST_CALIBRATION, payload,
			     sizeof(payload));
	if (err) {
		return err;
	}

	return drain_until_complete(usdio, shared_key, NULL, NULL);
}
```

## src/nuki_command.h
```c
/* nuki_command.h - encrypted Keyturner commands (state read, lock/unlock/
 * unlatch) over the USDIO characteristic, once a pairing exists.
 */
#ifndef NUKI_COMMAND_H_
#define NUKI_COMMAND_H_

#include "nuki_transport.h"
#include "nuki_protocol.h"
#include "nuki_crypto.h"

/* Reads the current Keyturner State (lock state, battery, door sensor...). */
int nuki_command_get_state(struct nuki_transport *usdio, uint32_t auth_id,
			    const uint8_t shared_key[NUKI_KEY_LEN],
			    struct nuki_keyturner_state *state);

/* Requests a fresh challenge and performs a lock action (see enum
 * nuki_lock_action). app_id must be the same one used during pairing.
 * Blocks until the lock reports Status COMPLETE (or an error/timeout).
 *
 * The lock conveniently pushes an intermediate KeyturnerStates update while
 * processing the action, sparing callers a separate nuki_command_get_state()
 * round trip. If state_out and got_state are both non-NULL, *got_state is
 * set to whether one was actually captured (best-effort - not guaranteed on
 * every action), and *state_out is only filled in that case. Pass NULL for
 * both if the caller doesn't need this.
 */
int nuki_command_lock_action(struct nuki_transport *usdio, uint32_t auth_id, uint32_t app_id,
			      const uint8_t shared_key[NUKI_KEY_LEN], uint8_t action,
			      struct nuki_keyturner_state *state_out, bool *got_state);

/* Requests a fresh challenge and triggers calibration: the lock rotates
 * through its full range once to relearn its mechanical end-stops (same
 * action the Nuki app performs during initial setup). Requires the lock's
 * Security-PIN (Smart Lock 1st-4th Generation: 4-digit, uint16). Blocks
 * until Status COMPLETE (or an error/timeout) - the lock may refuse with
 * an ErrorReport if the PIN is wrong or the battery is too low.
 */
int nuki_command_calibrate(struct nuki_transport *usdio, uint32_t auth_id,
			    const uint8_t shared_key[NUKI_KEY_LEN], uint16_t security_pin);

#endif /* NUKI_COMMAND_H_ */
```

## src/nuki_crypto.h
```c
/* nuki_crypto.h - Cryptographic primitives required by the Nuki Smart Lock
 * BLE API (see "Nuki Smart Lock API V2.3.0", section 4, "Encryption").
 *
 * Nuki bases its protocol on the NaCl Cryptography Toolbox:
 *   dh1   -> crypto_scalarmult_curve25519      (X25519 ECDH)
 *   kdf1  -> crypto_core_hsalsa20               (long-term key derivation)
 *   h1    -> HMAC-SHA256                        (authenticators)
 *   e1/d1 -> crypto_secretbox_xsalsa20poly1305   (encrypted command frames)
 *
 * X25519 and HMAC-SHA256 are delegated to the PSA Crypto API (available via
 * NCS nrf_security / mbedTLS). HSalsa20/Salsa20/Poly1305 have no PSA
 * equivalent (PSA only exposes ChaCha20-Poly1305, not the XSalsa20 variant
 * NaCl uses), so they are implemented here directly from the public NaCl/
 * djb reference algorithm.
 */
#ifndef NUKI_CRYPTO_H_
#define NUKI_CRYPTO_H_

#include <stdint.h>
#include <stddef.h>

#define NUKI_KEY_LEN     32
#define NUKI_NONCE_LEN   24
#define NUKI_TAG_LEN     16

/* Largest plaintext command payload (authId+cmdId+payload+crc) we ever
 * encrypt/decrypt. Generously covers every command used by this project.
 */
#define NUKI_CRYPTO_MAX_MSG_LEN 256

/* Must be called once (e.g. from main()) before any other nuki_crypto_*
 * function - initializes the PSA Crypto backend used for X25519 and
 * HMAC-SHA256.
 */
int nuki_crypto_init(void);

/* Generate a Curve25519 keypair for the initial pairing handshake. */
int nuki_crypto_keypair(uint8_t pub[NUKI_KEY_LEN], uint8_t priv[NUKI_KEY_LEN]);

/* dh1: X25519 scalar multiplication, out = priv * pub (raw ECDH result). */
int nuki_crypto_dh1(uint8_t out[NUKI_KEY_LEN], const uint8_t priv[NUKI_KEY_LEN],
		    const uint8_t pub[NUKI_KEY_LEN]);

/* kdf1: derive the long-term shared secret from the raw DH output. */
void nuki_crypto_kdf1(uint8_t out[NUKI_KEY_LEN], const uint8_t dh_result[NUKI_KEY_LEN]);

/* h1: HMAC-SHA256(key, data) used for all pairing authenticators. */
int nuki_crypto_h1(uint8_t out[32], const uint8_t key[NUKI_KEY_LEN],
		   const uint8_t *data, size_t len);

/*
 * e1: crypto_secretbox_xsalsa20poly1305.
 * out must be able to hold NUKI_TAG_LEN + msg_len bytes:
 *   out[0..16)          = Poly1305 authentication tag
 *   out[16..16+msg_len) = XSalsa20 ciphertext
 * Returns -EINVAL if msg_len > NUKI_CRYPTO_MAX_MSG_LEN.
 */
int nuki_crypto_e1(uint8_t *out, const uint8_t *msg, size_t msg_len,
		   const uint8_t nonce[NUKI_NONCE_LEN], const uint8_t key[NUKI_KEY_LEN]);

/*
 * d1: inverse of e1. in is tag(16) || ciphertext(msg_len).
 * Returns 0 and writes msg_len plaintext bytes to out on success,
 * -EBADMSG if the authentication tag does not match (out is not written).
 */
int nuki_crypto_d1(uint8_t *out, const uint8_t *in, size_t msg_len,
		   const uint8_t nonce[NUKI_NONCE_LEN], const uint8_t key[NUKI_KEY_LEN]);

/*
 * CRC16-CCITT ("normal"/non-reflected, poly 0x1021, init 0xFFFF) as used to
 * terminate every unencrypted and decrypted Nuki command payload. This is
 * NOT the same algorithm as Zephyr's crc16_ccitt() (which is the reflected
 * X.25/Kermit variant) - Nuki's "normal" representation matches Zephyr's
 * generic crc16(poly, seed, ...) instead.
 */
uint16_t nuki_crc16(const uint8_t *data, size_t len);

#endif /* NUKI_CRYPTO_H_ */
```

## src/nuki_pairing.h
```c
/* nuki_pairing.h - "Authorize App" handshake (Smart Lock 1st-4th Generation),
 * per "Nuki Smart Lock API V2.3.0", section 9. Runs entirely over the
 * unencrypted GDIO characteristic of the Pairing Service.
 */
#ifndef NUKI_PAIRING_H_
#define NUKI_PAIRING_H_

#include "nuki_transport.h"
#include "nuki_storage.h"

/* Blocks until pairing completes, fails, or times out (the lock must be in
 * pairing mode - button held 5s - before/while this runs). On success,
 * out->auth_id, out->shared_key and out->lock_uuid are filled in; the
 * caller fills out->addr from the active connection.
 *
 * Returns 0 on success, -ETIMEDOUT / -EBADMSG / -EIO on failure.
 */
int nuki_pairing_run(struct nuki_transport *gdio, struct nuki_pairing_data *out);

#endif /* NUKI_PAIRING_H_ */
```

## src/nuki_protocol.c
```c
#include "nuki_protocol.h"
#include "nuki_crypto.h"

#include <errno.h>
#include <string.h>
#include <zephyr/sys/byteorder.h>

const struct bt_uuid_128 nuki_pairing_service_uuid =
	BT_UUID_INIT_128(NUKI_PAIRING_SERVICE_UUID_VAL);
const struct bt_uuid_128 nuki_pairing_gdio_uuid = BT_UUID_INIT_128(NUKI_PAIRING_GDIO_UUID_VAL);
const struct bt_uuid_128 nuki_keyturner_service_uuid =
	BT_UUID_INIT_128(NUKI_KEYTURNER_SERVICE_UUID_VAL);
const struct bt_uuid_128 nuki_keyturner_usdio_uuid =
	BT_UUID_INIT_128(NUKI_KEYTURNER_USDIO_UUID_VAL);

size_t nuki_frame_build_plain(uint8_t *out, size_t out_size, uint16_t command_id,
			       const uint8_t *payload, size_t payload_len)
{
	size_t total = 2 + payload_len + 2;

	if (total > out_size) {
		return 0;
	}

	sys_put_le16(command_id, out);
	if (payload_len) {
		memcpy(out + 2, payload, payload_len);
	}
	uint16_t crc = nuki_crc16(out, 2 + payload_len);

	sys_put_le16(crc, out + 2 + payload_len);
	return total;
}

int nuki_frame_parse_plain(const uint8_t *frame, size_t frame_len, uint16_t *command_id,
			    const uint8_t **payload, size_t *payload_len)
{
	if (frame_len < 4) {
		return -EINVAL;
	}

	size_t body_len = frame_len - 2;
	uint16_t expected_crc = nuki_crc16(frame, body_len);
	uint16_t got_crc = sys_get_le16(frame + body_len);

	if (expected_crc != got_crc) {
		return -EBADMSG;
	}

	*command_id = sys_get_le16(frame);
	*payload = frame + 2;
	*payload_len = body_len - 2;
	return 0;
}

size_t nuki_frame_build_auth(uint8_t *out, size_t out_size, uint32_t auth_id, uint16_t command_id,
			     const uint8_t *payload, size_t payload_len)
{
	size_t total = 4 + 2 + payload_len + 2;

	if (total > out_size) {
		return 0;
	}

	sys_put_le32(auth_id, out);
	sys_put_le16(command_id, out + 4);
	if (payload_len) {
		memcpy(out + 6, payload, payload_len);
	}
	uint16_t crc = nuki_crc16(out, 6 + payload_len);

	sys_put_le16(crc, out + 6 + payload_len);
	return total;
}

int nuki_frame_parse_auth(const uint8_t *frame, size_t frame_len, uint32_t *auth_id,
			   uint16_t *command_id, const uint8_t **payload, size_t *payload_len)
{
	if (frame_len < 8) {
		return -EINVAL;
	}

	size_t body_len = frame_len - 2;
	uint16_t expected_crc = nuki_crc16(frame, body_len);
	uint16_t got_crc = sys_get_le16(frame + body_len);

	if (expected_crc != got_crc) {
		return -EBADMSG;
	}

	*auth_id = sys_get_le32(frame);
	*command_id = sys_get_le16(frame + 4);
	*payload = frame + 6;
	*payload_len = body_len - 6;
	return 0;
}

int nuki_keyturner_state_parse(struct nuki_keyturner_state *state, const uint8_t *payload,
				size_t len)
{
	/* Fixed prefix common to every Smart Lock generation (API section
	 * 5, "Keyturner States"): nukiState, lockState, trigger,
	 * currentTime[7], timezoneOffset, criticalBatteryState.
	 */
	if (len < 13) {
		return -EINVAL;
	}

	memset(state, 0, sizeof(*state));
	state->nuki_state = payload[0];
	state->lock_state = payload[1];
	state->trigger = payload[2];
	state->year = sys_get_le16(&payload[3]);
	state->month = payload[5];
	state->day = payload[6];
	state->hour = payload[7];
	state->minute = payload[8];
	state->second = payload[9];
	state->timezone_offset_min = (int16_t)sys_get_le16(&payload[10]);
	state->critical_battery = payload[12] & 0x01;
	state->battery_percent = (uint8_t)((payload[12] >> 2) * 2);
	state->door_sensor_state = 0xFF;

	/* Optional trailing fields (configUpdateCount, lockNgoTimer,
	 * lastLockAction, lastLockActionTrigger,
	 * lastLockActionCompletionStatus, doorSensorState, ...).
	 */
	if (len >= 19) {
		state->door_sensor_state = payload[18];
	}

	return 0;
}

const char *nuki_lock_state_to_str(uint8_t lock_state)
{
	switch (lock_state) {
	case 0x00:
		return "uncalibrated";
	case 0x01:
		return "locked";
	case 0x02:
		return "unlocking";
	case 0x03:
		return "unlocked";
	case 0x04:
		return "locking";
	case 0x05:
		return "unlatched";
	case 0x06:
		return "unlocked (lock'n'go active)";
	case 0x07:
		return "unlatching";
	case 0xFC:
		return "calibration";
	case 0xFD:
		return "boot run";
	case 0xFE:
		return "motor blocked";
	default:
		return "undefined";
	}
}

const char *nuki_door_sensor_state_to_str(uint8_t state)
{
	switch (state) {
	case 0x00:
		return "unavailable";
	case 0x01:
		return "deactivated";
	case 0x02:
		return "door closed";
	case 0x03:
		return "door opened";
	case 0x04:
		return "door state unknown";
	case 0x05:
		return "calibrating";
	case 0x10:
		return "uncalibrated";
	case 0xF0:
		return "tampered";
	default:
		return "unknown";
	}
}
```
